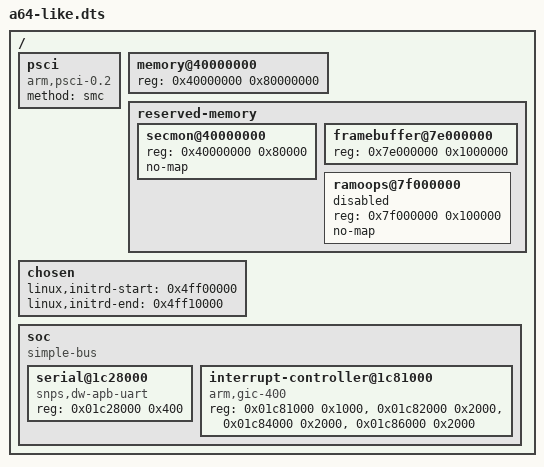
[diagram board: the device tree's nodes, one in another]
// SPDX-License-Identifier: GPL-3.0-or-later
// Copyright (C) 2026 Sergey Subbotin <ssubbotin@gmail.com>
/dts-v1/;
/ {
	#address-cells = <1>;
	#size-cells = <1>;

	psci {
		compatible = "arm,psci-0.2";
		method = "smc";
	};

	memory@40000000 {
		device_type = "memory";
		reg = <0x40000000 0x80000000>;
	};

	reserved-memory {
		#address-cells = <1>;
		#size-cells = <1>;
		ranges;

		secmon@40000000 {
			reg = <0x40000000 0x80000>;
			no-map;
		};

		framebuffer@7e000000 {
			reg = <0x7e000000 0x1000000>;
		};

		ramoops@7f000000 {
			reg = <0x7f000000 0x100000>;
			no-map;
			status = "disabled";
		};
	};

	chosen {
		linux,initrd-start = <0x4ff00000>;
		linux,initrd-end = <0x4ff10000>;
	};

	soc {
		compatible = "simple-bus";
		#address-cells = <1>;
		#size-cells = <1>;
		ranges;

		serial@1c28000 {
			compatible = "snps,dw-apb-uart";
			reg = <0x01c28000 0x400>;
		};

		interrupt-controller@1c81000 {
			compatible = "arm,gic-400";
			reg = <0x01c81000 0x1000>, <0x01c82000 0x2000>,
			      <0x01c84000 0x2000>, <0x01c86000 0x2000>;
		};
	};
};
